# f29h85x_erad_regs register map
Vendor: Texas Instruments
Peripheral module from a debugger description file (folder C29).
Registers are 32-bit, read-write, no defined reset value unless marked. A register's access mark holds for its fields unless they carry their own. Offsets are as the file gives them; lines under a group give offsets from that group; [hi:lo] are bit positions; {n}, {i} and the like mark numbered series; 'fields as' and 'values as' point back to an identical list; <NAME> marks a mode.

## ERAD_REGS — ERAD Registers
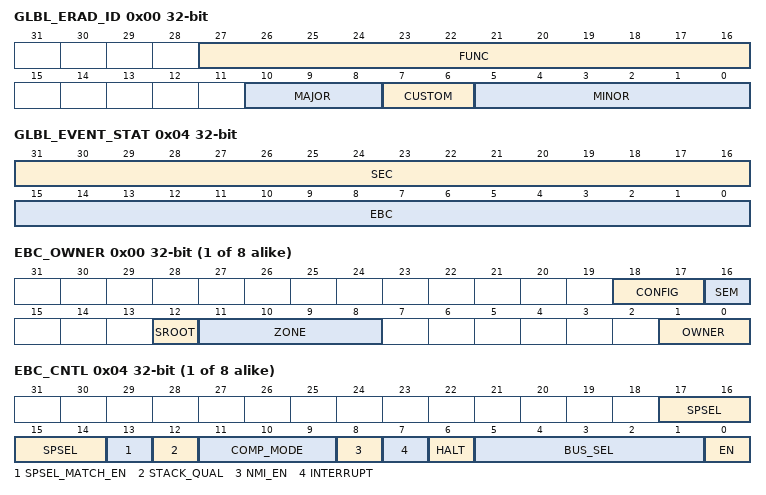
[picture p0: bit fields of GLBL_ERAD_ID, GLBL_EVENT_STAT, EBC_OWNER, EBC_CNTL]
0x00 GLBL_ERAD_ID ro — Debug Peripheral ID
  [27:16] FUNC, [10:8] MAJOR, [7:6] CUSTOM, [5:0] MINOR
0x04 GLBL_EVENT_STAT ro — Global Event Status Register
  [31:16] SEC — SEC Module Event Status
  [15:0] EBC — EBC Module Event Status
{0x40+0x40*i} ERAD_EBC_REGS[{i}] (i=0..7) group
  0x00 EBC_OWNER access per field
    [18:17] CONFIG ro — Configuration
    [16] SEM ro — Semaphore
    [12] SROOT ro — SROOT LINK ownership
    [11:8] ZONE ro — Zone ID
    [1:0] OWNER rw — Ownership ID
  0x04 EBC_CNTL — EBC Control Register
    [17:14] SPSEL
    [13] SPSEL_MATCH_EN — SPSEL match enable
    [12] STACK_QUAL — Stack access qualifier
    [11:9] COMP_MODE — Compare mode
    [8] NMI_EN — NMI enable
    [7] INTERRUPT — Interrupt enable
    [6] HALT — CPU Halt
    [5:1] BUS_SEL — Bus select bits
    [0] EN — Enable
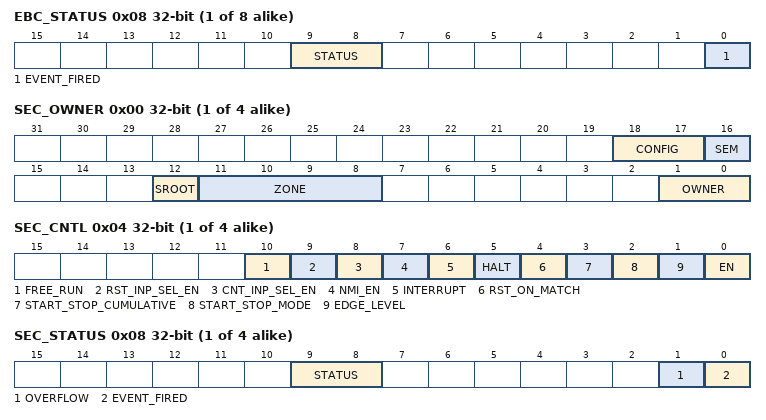
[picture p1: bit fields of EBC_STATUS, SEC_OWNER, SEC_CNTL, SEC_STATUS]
  0x08 EBC_STATUS ro
    [9:8] STATUS — Status bits
    [0] EVENT_FIRED — EBC Event Fired bits
  0x0C EBC_STATUSCLEAR — EBC Clear Register
    [0] EVENT_FIRED — Event Clear register
  0x10 EBC_REFL — EBC Reference Low Register
    [31:0] REF — Compare low reference register
  0x14 EBC_REFH — EBC Reference High Register
    [31:0] REF — Compare high reference register
  0x18 EBC_MASKL — EBC Mask Low Register
    [31:0] MASK — Compare low mask register
  0x1C EBC_MASKH — EBC Mask High Register
    [31:0] MASK — Compare high mask register
  0x20 EBC_WP_PC ro — EBC Watchpoint PC Register
    [31:0] PC — Watchpoint PC Register
{0x440+0x40*i} ERAD_SEC_REGS[{i}] (i=0..3) group
  0x00 SEC_OWNER access per field
    fields as ERAD_EBC_REGS[0].EBC_OWNER
  0x04 SEC_CNTL — SEC Control Register
    [10] FREE_RUN — counter behaviour on CPU Halt
    [9] RST_INP_SEL_EN — Counter reset input select enable
    [8] CNT_INP_SEL_EN — Counter input select enable
    [7] NMI_EN — NMI enable
    [6] INTERRUPT — Interrupt enable
    [5] HALT — CPU Halt
    [4] RST_ON_MATCH — Reset_on_match bit
    [3] START_STOP_CUMULATIVE — Start stop cumulative bit
    [2] START_STOP_MODE — Start_stop mode bit
    [1] EDGE_LEVEL — Event mode bit
    [0] EN — Enable
  0x08 SEC_STATUS ro
    [9:8] STATUS — Status bits
    [1] OVERFLOW — Counter Overflowed
    [0] EVENT_FIRED — Counter Event Fired bits
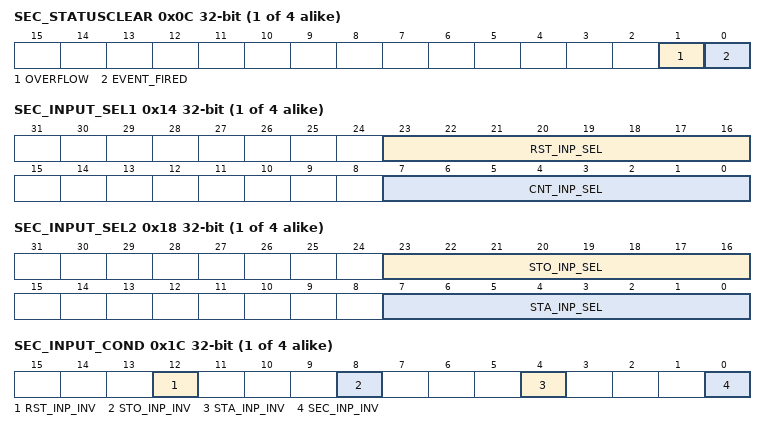
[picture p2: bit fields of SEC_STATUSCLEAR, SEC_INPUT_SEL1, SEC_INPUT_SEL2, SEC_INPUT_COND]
  0x0C SEC_STATUSCLEAR — SEC Clear Register
    [1] OVERFLOW — Clear OVERFLOW
    [0] EVENT_FIRED — Clear EVENT_FIRED
  0x10 SEC_REF — SEC Reference Register
    [31:0] REF — Counter reference/compare register
  0x14 SEC_INPUT_SEL1 — SEC Input Select Register1
    [23:16] RST_INP_SEL — Counter Reset input Select
    [7:0] CNT_INP_SEL — Counter Input Select
  0x18 SEC_INPUT_SEL2 — SEC Input Select Register2
    [23:16] STO_INP_SEL — Counter Stop Input Select
    [7:0] STA_INP_SEL — Counter Sart Input Select
  0x1C SEC_INPUT_COND — SEC Input Conditioning Register
    [12] RST_INP_INV — Reset input Invert
    [8] STO_INP_INV — Stop input Invert
    [4] STA_INP_INV — Start input Invert
    [0] SEC_INP_INV — Counter Input Invert
  0x20 SEC_COUNT — SEC Counter Register
    [31:0] COUNT — The counter value register
  0x24 SEC_MAX_COUNT
    [31:0] MAX_COUNT — The maximum recorded counter value.
  0x28 SEC_MIN_COUNT
    [31:0] MIN_COUNT — The minimum recorded counter value.
{0x640+0x20*i} ERAD_AND_REGS[{i}] (i=0..3) group
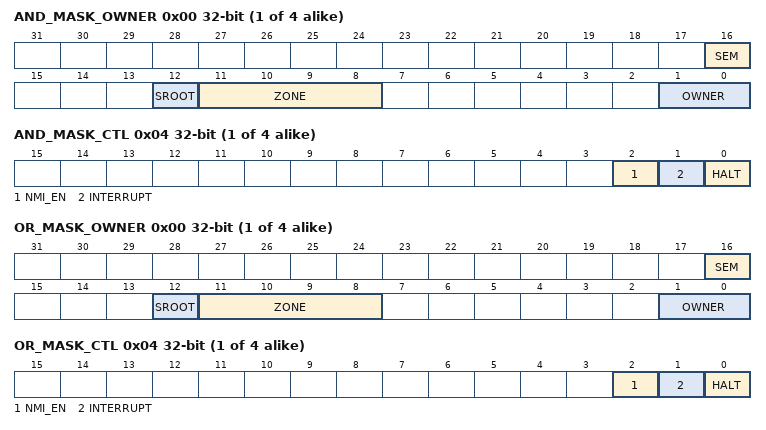
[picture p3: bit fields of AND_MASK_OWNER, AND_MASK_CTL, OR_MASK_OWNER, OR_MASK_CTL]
  0x00 AND_MASK_OWNER access per field — AND Owner Register
    [16] SEM ro — Semaphore
    [12] SROOT ro — SROOT LINK ownership
    [11:8] ZONE ro — Zone ID
    [1:0] OWNER rw — Ownership ID
  0x04 AND_MASK_CTL — AND Control Register
    [2] NMI_EN — NMI enable
    [1] INTERRUPT — Interrupt enable
    [0] HALT — CPU Halt
  0x08 EVENT_AND_MASK — AND Event Selection Register
    [23:0] MASK_EBC — EBC, SEC AND Event Mask
{0x740+0x20*i} ERAD_OR_REGS[{i}] (i=0..3) group
  0x00 OR_MASK_OWNER access per field — OR Owner Register
    fields as ERAD_AND_REGS[0].AND_MASK_OWNER
  0x04 OR_MASK_CTL — OR Control Register
    fields as ERAD_AND_REGS[0].AND_MASK_CTL
  0x08 EVENT_OR_MASK — OR Event Selection Register
    [23:0] MASK_EBC — EBC, SEC OR Event Mask
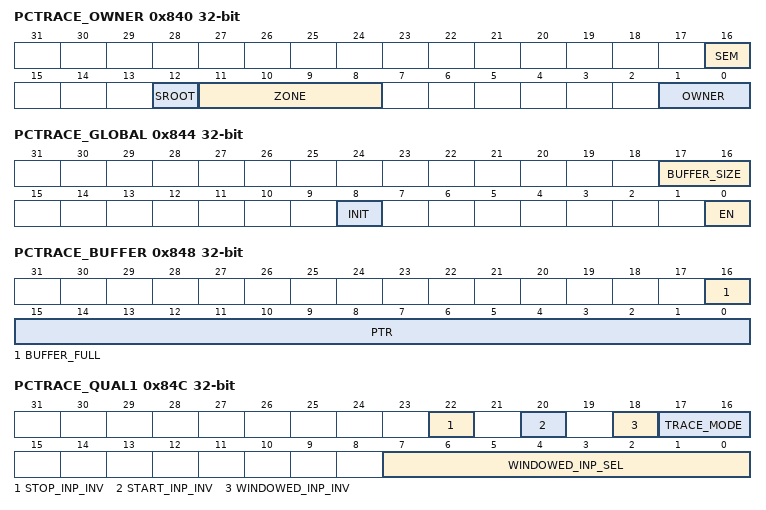
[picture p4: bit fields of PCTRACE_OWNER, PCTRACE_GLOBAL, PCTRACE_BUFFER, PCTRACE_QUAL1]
0x840 PCTRACE_OWNER access per field — Owner Register
  fields as ERAD_AND_REGS[0].AND_MASK_OWNER
0x844 PCTRACE_GLOBAL access per field — Global Control Register
  [17:16] BUFFER_SIZE ro — Trace buffer size
  [8] INIT rw — Initialize the PC Trace and buffer pointer
  [0] EN rw — Enable PC trace
0x848 PCTRACE_BUFFER ro — Trace Buffer pointer register
  [16] BUFFER_FULL — Trace Buffer Full
  [15:0] PTR — Trace Buffer Pointer
0x84C PCTRACE_QUAL1 — Trace Qualifier register 1
  [22] STOP_INP_INV — Stop input Invert
  [20] START_INP_INV — Start input Invert
  [18] WINDOWED_INP_INV — Windowed trace Input Invert
  [17:16] TRACE_MODE — Trace qualifier mode
  [7:0] WINDOWED_INP_SEL — Windowed trace qualifier
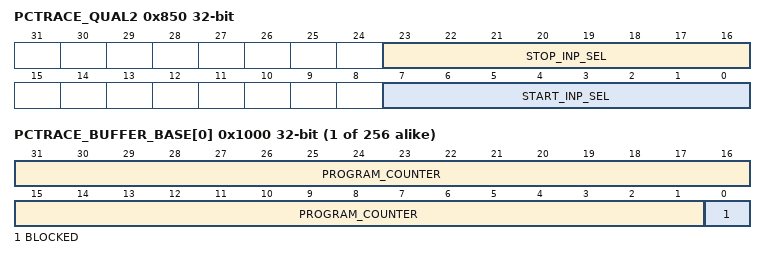
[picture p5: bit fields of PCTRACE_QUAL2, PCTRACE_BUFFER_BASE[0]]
0x850 PCTRACE_QUAL2 — Trace Qualifier register 2
  [23:16] STOP_INP_SEL — Trace Stop event select
  [7:0] START_INP_SEL — Trace Start event select
0x854 PCTRACE_LOGPC_SOFTENABLE ro — PC when PC Trace was last enabled by software
  [31:0] PC_SOFTENABLE
0x858 PCTRACE_LOGPC_SOFTDISABLE ro — PC when PC Trace was last disabled by software
  [31:0] PC_SOFTDISABLE
{0x1000+4i} PCTRACE_BUFFER_BASE[{i}] (i=0..255) ro — Trace Buffer Base address
  [31:1] PROGRAM_COUNTER
  [0] BLOCKED — Access blocked due to security
